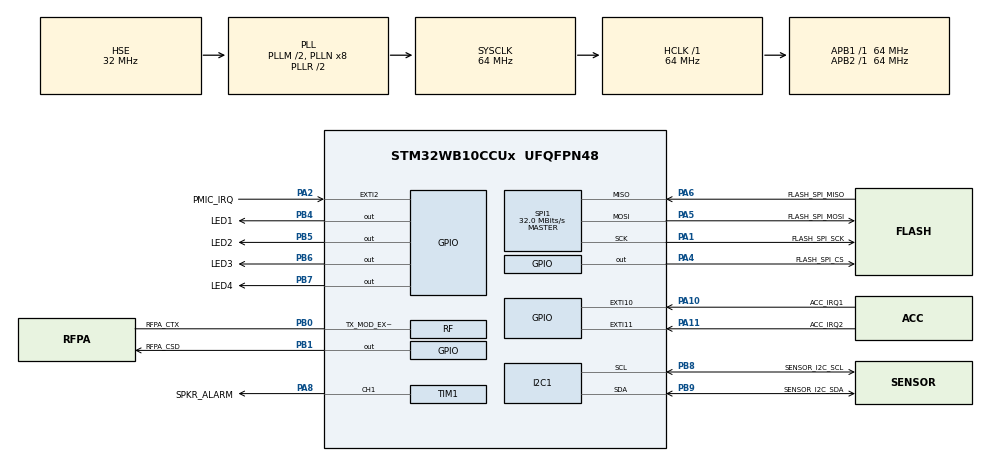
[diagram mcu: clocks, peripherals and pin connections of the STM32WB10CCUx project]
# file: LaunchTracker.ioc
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I2C1.Timing=0x10707DBC
Mcu.Family=STM32WB
Mcu.Name=STM32WB10CCUx
Mcu.Package=UFQFPN48
NVIC.EXTI15_10_IRQn=true\:0\:0\:false\:false\:true\:true\:true\:true
NVIC.HSEM_IRQn=true\:0\:0\:false\:false\:true\:false\:true\:true
NVIC.IPCC_C1_RX_IRQn=true\:0\:0\:false\:false\:true\:true\:true\:true
NVIC.IPCC_C1_TX_IRQn=true\:0\:0\:false\:false\:true\:true\:true\:true
NVIC.PriorityGroup=NVIC_PRIORITYGROUP_4
OSC_IN.Mode=HSE-External-Oscillator
OSC_IN.Signal=RCC_OSC_IN
OSC_OUT.Mode=HSE-External-Oscillator
OSC_OUT.Signal=RCC_OSC_OUT
PA1.GPIO_Label=FLASH_SPI_SCK
PA1.Mode=Full_Duplex_Master
PA1.Signal=SPI1_SCK
PA10.GPIO_Label=ACC_IRQ1
PA10.GPIO_ModeDefaultEXTI=GPIO_MODE_IT_FALLING
PA10.GPIO_PuPd=GPIO_PULLUP
PA10.Signal=GPXTI10
PA11.GPIO_Label=ACC_IRQ2
PA11.GPIO_ModeDefaultEXTI=GPIO_MODE_IT_FALLING
PA11.GPIO_PuPd=GPIO_PULLUP
PA11.Signal=GPXTI11
PA13.Mode=Trace_Asynchronous_SW
PA13.Signal=SYS_JTMS-SWDIO
PA14.Mode=Trace_Asynchronous_SW
PA14.Signal=SYS_JTCK-SWCLK
PA2.GPIO_Label=PMIC_IRQ
PA2.GPIO_ModeDefaultEXTI=GPIO_MODE_IT_FALLING
PA2.GPIO_PuPd=GPIO_PULLUP
PA2.Signal=GPXTI2
PA4.GPIO_Label=FLASH_SPI_CS
PA4.GPIO_ModeDefaultOutputPP=GPIO_MODE_OUTPUT_OD
PA4.GPIO_PuPd=GPIO_PULLUP
PA4.PinState=GPIO_PIN_SET
PA4.Signal=GPIO_Output
PA5.GPIO_Label=FLASH_SPI_MOSI
PA5.Mode=Full_Duplex_Master
PA5.Signal=SPI1_MOSI
PA6.GPIO_Label=FLASH_SPI_MISO
PA6.Mode=Full_Duplex_Master
PA6.Signal=SPI1_MISO
PA8.GPIO_Label=SPKR_ALARM
PA8.Signal=S_TIM1_CH1
PB0.GPIO_Label=RFPA_CTX
PB0.Mode=TX_MOD_EXT_PA
PB0.Signal=RF_TX_MOD_EXT_PA
PB1.GPIO_Label=RFPA_CSD
PB1.Signal=GPIO_Output
PB3.Mode=Trace_Asynchronous_SW
PB3.Signal=SYS_JTDO-SWO
PB4.GPIO_Label=LED1
PB4.Signal=GPIO_Output
PB5.GPIO_Label=LED2
PB5.Signal=GPIO_Output
PB6.GPIO_Label=LED3
PB6.Signal=GPIO_Output
PB7.GPIO_Label=LED4
PB7.Signal=GPIO_Output
PB8.GPIO_Label=SENSOR_I2C_SCL
PB8.Mode=I2C
PB8.Signal=I2C1_SCL
PB9.GPIO_Label=SENSOR_I2C_SDA
PB9.Mode=I2C
PB9.Signal=I2C1_SDA
PC14-OSC32_IN.Mode=LSE-External-Oscillator
PC14-OSC32_IN.Signal=RCC_OSC32_IN
PC15-OSC32_OUT.Mode=LSE-External-Oscillator
PC15-OSC32_OUT.Signal=RCC_OSC32_OUT
ProjectManager.HeapSize=0x200
ProjectManager.StackSize=0x400
ProjectManager.TargetToolchain=STM32CubeIDE
RCC.ADCFreq_Value=64000000
RCC.AHB2CLKDivider=RCC_SYSCLK_DIV2
RCC.AHBFreq_Value=64000000
RCC.APB1Freq_Value=64000000
RCC.APB1TimFreq_Value=64000000
RCC.APB2Freq_Value=64000000
RCC.APB2TimFreq_Value=64000000
RCC.APB3Freq_Value=16000000
RCC.CortexFreq_Value=64000000
RCC.HCLKFreq_Value=64000000
RCC.HSE_VALUE=32000000
RCC.HSI_VALUE=16000000
RCC.PLLM=RCC_PLLM_DIV2
RCC.PLLSourceVirtual=RCC_PLLSOURCE_HSE
RCC.RFWKPClockSelection=RCC_RFWKPCLKSOURCE_LSE
RCC.RTCClockSelection=RCC_RTCCLKSOURCE_LSE
RCC.SYSCLKFreq_VALUE=64000000
RCC.SYSCLKSource=RCC_SYSCLKSOURCE_PLLCLK
RCC.VCOOutputFreq_Value=128000000
RF1.Mode=RF1_Activate
RF1.Signal=RF_RF1
SH.S_TIM1_CH1.0=TIM1_CH1,PWM Generation1 CH1
SPI1.CalculateBaudRate=32.0 MBits/s
SPI1.Direction=SPI_DIRECTION_2LINES
SPI1.Mode=SPI_MODE_MASTER
SPI1.VirtualType=VM_MASTER
STM32_WPAN.CFG_LPM_SUPPORTED=1
STM32_WPAN.CFG_TX_POWER=(0x1D) /* 4dBm */
TIM1.Channel-PWM\ Generation1\ CH1=TIM_CHANNEL_1
VP_HSEM_VS_HSEM.Mode=HSEM_Activate
VP_IPCC_VS_IPCC.Mode=IPCC_Activate
VP_MEMORYMAP_VS_MEMORYMAP.Mode=CurAppReg
VP_RTC_VS_RTC_Activate.Mode=RTC_Enabled
VP_SEQUENCER_VS_SEQUENCER.Mode=SEQUENCER_Enabled
VP_STM32_WPAN_VS_BLE_HOST.Mode=STM32_WPAN_Enabled
VP_TINY_LPM_VS_TINY_LPM.Mode=TINY_LPM_Enabled
board=custom

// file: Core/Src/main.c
/* USER CODE BEGIN Header */
/**
  ******************************************************************************
  * @file           : main.c
  * @brief          : Main program body
  ******************************************************************************
  * @attention
  *
  * Copyright (c) 2024 STMicroelectronics.
  * All rights reserved.
  *
  * This software is licensed under terms that can be found in the LICENSE file
  * in the root directory of this software component.
  * If no LICENSE file comes with this software, it is provided AS-IS.
  *
  ******************************************************************************
  */
/* USER CODE END Header */
#include "main.h"

/* USER CODE BEGIN Includes */
#include "LT_App.h"
/* USER CODE END Includes */

I2C_HandleTypeDef hi2c1;

IPCC_HandleTypeDef hipcc;

RTC_HandleTypeDef hrtc;

SPI_HandleTypeDef hspi1;

TIM_HandleTypeDef htim1;

void SystemClock_Config(void);
void PeriphCommonClock_Config(void);
static void MX_GPIO_Init(void);
static void MX_I2C1_Init(void);
static void MX_IPCC_Init(void);
static void MX_RTC_Init(void);
static void MX_SPI1_Init(void);
static void MX_TIM1_Init(void);
static void MX_RF_Init(void);

int main(void)
{

  /* MCU Configuration--------------------------------------------------------*/

  /* Reset of all peripherals, Initializes the Flash interface and the Systick. */
  HAL_Init();
  /* Config code for STM32_WPAN (HSE Tuning must be done before system clock configuration) */
  MX_APPE_Config();

  /* Configure the system clock */
  SystemClock_Config();

/* Configure the peripherals common clocks */
  PeriphCommonClock_Config();

  /* IPCC initialisation */
  MX_IPCC_Init();

  /* Initialize all configured peripherals */
  MX_GPIO_Init();
  MX_I2C1_Init();
  MX_RTC_Init();
  MX_SPI1_Init();
  MX_TIM1_Init();
  MX_RF_Init();
  /* USER CODE BEGIN 2 */
//  ltHWInit();
  /* USER CODE END 2 */

  /* Init code for STM32_WPAN */
  MX_APPE_Init();

  /* Infinite loop */
  while (1)
  {
    MX_APPE_Process();

  }
}

void SystemClock_Config(void)
{
  RCC_OscInitTypeDef RCC_OscInitStruct = {0};
  RCC_ClkInitTypeDef RCC_ClkInitStruct = {0};

  /** Configure LSE Drive Capability
  */
  HAL_PWR_EnableBkUpAccess();
  __HAL_RCC_LSEDRIVE_CONFIG(RCC_LSEDRIVE_MEDIUMHIGH);

  /** Initializes the RCC Oscillators according to the specified parameters
  * in the RCC_OscInitTypeDef structure.
  */
  RCC_OscInitStruct.OscillatorType = RCC_OSCILLATORTYPE_HSI|RCC_OSCILLATORTYPE_HSE
                              |RCC_OSCILLATORTYPE_LSE;
  RCC_OscInitStruct.HSEState = RCC_HSE_ON;
  RCC_OscInitStruct.LSEState = RCC_LSE_ON;
  RCC_OscInitStruct.HSIState = RCC_HSI_ON;
  RCC_OscInitStruct.HSICalibrationValue = RCC_HSICALIBRATION_DEFAULT;
  RCC_OscInitStruct.PLL.PLLState = RCC_PLL_ON;
  RCC_OscInitStruct.PLL.PLLSource = RCC_PLLSOURCE_HSE;
  RCC_OscInitStruct.PLL.PLLM = RCC_PLLM_DIV2;
  RCC_OscInitStruct.PLL.PLLN = 8;
  RCC_OscInitStruct.PLL.PLLP = RCC_PLLP_DIV2;
  RCC_OscInitStruct.PLL.PLLR = RCC_PLLR_DIV2;
  RCC_OscInitStruct.PLL.PLLQ = RCC_PLLQ_DIV2;
  if (HAL_RCC_OscConfig(&RCC_OscInitStruct) != HAL_OK)
  {
    Error_Handler();
  }

  /** Configure the SYSCLKSource, HCLK, PCLK1 and PCLK2 clocks dividers
  */
  RCC_ClkInitStruct.ClockType = RCC_CLOCKTYPE_HCLK4|RCC_CLOCKTYPE_HCLK2
                              |RCC_CLOCKTYPE_HCLK|RCC_CLOCKTYPE_SYSCLK
                              |RCC_CLOCKTYPE_PCLK1|RCC_CLOCKTYPE_PCLK2;
  RCC_ClkInitStruct.SYSCLKSource = RCC_SYSCLKSOURCE_PLLCLK;
  RCC_ClkInitStruct.AHBCLKDivider = RCC_SYSCLK_DIV1;
  RCC_ClkInitStruct.APB1CLKDivider = RCC_HCLK_DIV1;
  RCC_ClkInitStruct.APB2CLKDivider = RCC_HCLK_DIV1;
  RCC_ClkInitStruct.AHBCLK2Divider = RCC_SYSCLK_DIV2;
  RCC_ClkInitStruct.AHBCLK4Divider = RCC_SYSCLK_DIV1;

  if (HAL_RCC_ClockConfig(&RCC_ClkInitStruct, FLASH_LATENCY_3) != HAL_OK)
  {
    Error_Handler();
  }
}

void PeriphCommonClock_Config(void)
{
  RCC_PeriphCLKInitTypeDef PeriphClkInitStruct = {0};

  /** Initializes the peripherals clock
  */
  PeriphClkInitStruct.PeriphClockSelection = RCC_PERIPHCLK_RFWAKEUP;
  PeriphClkInitStruct.RFWakeUpClockSelection = RCC_RFWKPCLKSOURCE_LSE;
  if (HAL_RCCEx_PeriphCLKConfig(&PeriphClkInitStruct) != HAL_OK)
  {
    Error_Handler();
  }
}

static void MX_I2C1_Init(void)
{

  hi2c1.Instance = I2C1;
  hi2c1.Init.Timing = 0x10707DBC;
  hi2c1.Init.OwnAddress1 = 0;
  hi2c1.Init.AddressingMode = I2C_ADDRESSINGMODE_7BIT;
  hi2c1.Init.DualAddressMode = I2C_DUALADDRESS_DISABLE;
  hi2c1.Init.OwnAddress2 = 0;
  hi2c1.Init.OwnAddress2Masks = I2C_OA2_NOMASK;
  hi2c1.Init.GeneralCallMode = I2C_GENERALCALL_DISABLE;
  hi2c1.Init.NoStretchMode = I2C_NOSTRETCH_DISABLE;
  if (HAL_I2C_Init(&hi2c1) != HAL_OK)
  {
    Error_Handler();
  }

  /** Configure Analogue filter
  */
  if (HAL_I2CEx_ConfigAnalogFilter(&hi2c1, I2C_ANALOGFILTER_ENABLE) != HAL_OK)
  {
    Error_Handler();
  }

  /** Configure Digital filter
  */
  if (HAL_I2CEx_ConfigDigitalFilter(&hi2c1, 0) != HAL_OK)
  {
    Error_Handler();
  }

}

static void MX_IPCC_Init(void)
{

  hipcc.Instance = IPCC;
  if (HAL_IPCC_Init(&hipcc) != HAL_OK)
  {
    Error_Handler();
  }

}

static void MX_RF_Init(void)
{

}

static void MX_RTC_Init(void)
{

  /** Initialize RTC Only
  */
  hrtc.Instance = RTC;
  hrtc.Init.HourFormat = RTC_HOURFORMAT_24;
  hrtc.Init.AsynchPrediv = CFG_RTC_ASYNCH_PRESCALER;
  hrtc.Init.SynchPrediv = CFG_RTC_SYNCH_PRESCALER;
  hrtc.Init.OutPut = RTC_OUTPUT_DISABLE;
  hrtc.Init.OutPutPolarity = RTC_OUTPUT_POLARITY_HIGH;
  hrtc.Init.OutPutRemap = RTC_OUTPUT_REMAP_NONE;
  if (HAL_RTC_Init(&hrtc) != HAL_OK)
  {
    Error_Handler();
  }

}

static void MX_SPI1_Init(void)
{

  /* SPI1 parameter configuration*/
  hspi1.Instance = SPI1;
  hspi1.Init.Mode = SPI_MODE_MASTER;
  hspi1.Init.Direction = SPI_DIRECTION_2LINES;
  hspi1.Init.DataSize = SPI_DATASIZE_8BIT;
  hspi1.Init.CLKPolarity = SPI_POLARITY_LOW;
  hspi1.Init.CLKPhase = SPI_PHASE_1EDGE;
  hspi1.Init.NSS = SPI_NSS_SOFT;
  hspi1.Init.BaudRatePrescaler = SPI_BAUDRATEPRESCALER_2;
  hspi1.Init.FirstBit = SPI_FIRSTBIT_MSB;
  hspi1.Init.TIMode = SPI_TIMODE_DISABLE;
  hspi1.Init.CRCCalculation = SPI_CRCCALCULATION_DISABLE;
  hspi1.Init.CRCPolynomial = 7;
  hspi1.Init.CRCLength = SPI_CRC_LENGTH_DATASIZE;
  hspi1.Init.NSSPMode = SPI_NSS_PULSE_ENABLE;
  if (HAL_SPI_Init(&hspi1) != HAL_OK)
  {
    Error_Handler();
  }

}

static void MX_TIM1_Init(void)
{

  TIM_MasterConfigTypeDef sMasterConfig = {0};
  TIM_OC_InitTypeDef sConfigOC = {0};
  TIM_BreakDeadTimeConfigTypeDef sBreakDeadTimeConfig = {0};

  htim1.Instance = TIM1;
  htim1.Init.Prescaler = 0;
  htim1.Init.CounterMode = TIM_COUNTERMODE_UP;
  htim1.Init.Period = 65535;
  htim1.Init.ClockDivision = TIM_CLOCKDIVISION_DIV1;
  htim1.Init.RepetitionCounter = 0;
  htim1.Init.AutoReloadPreload = TIM_AUTORELOAD_PRELOAD_DISABLE;
  if (HAL_TIM_PWM_Init(&htim1) != HAL_OK)
  {
    Error_Handler();
  }
  sMasterConfig.MasterOutputTrigger = TIM_TRGO_RESET;
  sMasterConfig.MasterOutputTrigger2 = TIM_TRGO2_RESET;
  sMasterConfig.MasterSlaveMode = TIM_MASTERSLAVEMODE_DISABLE;
  if (HAL_TIMEx_MasterConfigSynchronization(&htim1, &sMasterConfig) != HAL_OK)
  {
    Error_Handler();
  }
  sConfigOC.OCMode = TIM_OCMODE_PWM1;
  sConfigOC.Pulse = 0;
  sConfigOC.OCPolarity = TIM_OCPOLARITY_HIGH;
  sConfigOC.OCNPolarity = TIM_OCNPOLARITY_HIGH;
  sConfigOC.OCFastMode = TIM_OCFAST_DISABLE;
  sConfigOC.OCIdleState = TIM_OCIDLESTATE_RESET;
  sConfigOC.OCNIdleState = TIM_OCNIDLESTATE_RESET;
  if (HAL_TIM_PWM_ConfigChannel(&htim1, &sConfigOC, TIM_CHANNEL_1) != HAL_OK)
  {
    Error_Handler();
  }
  sBreakDeadTimeConfig.OffStateRunMode = TIM_OSSR_DISABLE;
  sBreakDeadTimeConfig.OffStateIDLEMode = TIM_OSSI_DISABLE;
  sBreakDeadTimeConfig.LockLevel = TIM_LOCKLEVEL_OFF;
  sBreakDeadTimeConfig.DeadTime = 0;
  sBreakDeadTimeConfig.BreakState = TIM_BREAK_DISABLE;
  sBreakDeadTimeConfig.BreakPolarity = TIM_BREAKPOLARITY_HIGH;
  sBreakDeadTimeConfig.BreakFilter = 0;
  sBreakDeadTimeConfig.BreakAFMode = TIM_BREAK_AFMODE_INPUT;
  sBreakDeadTimeConfig.Break2State = TIM_BREAK2_DISABLE;
  sBreakDeadTimeConfig.Break2Polarity = TIM_BREAK2POLARITY_HIGH;
  sBreakDeadTimeConfig.Break2Filter = 0;
  sBreakDeadTimeConfig.Break2AFMode = TIM_BREAK_AFMODE_INPUT;
  sBreakDeadTimeConfig.AutomaticOutput = TIM_AUTOMATICOUTPUT_DISABLE;
  if (HAL_TIMEx_ConfigBreakDeadTime(&htim1, &sBreakDeadTimeConfig) != HAL_OK)
  {
    Error_Handler();
  }
  HAL_TIM_MspPostInit(&htim1);

}

static void MX_GPIO_Init(void)
{
  GPIO_InitTypeDef GPIO_InitStruct = {0};

  /* GPIO Ports Clock Enable */
  __HAL_RCC_GPIOC_CLK_ENABLE();
  __HAL_RCC_GPIOB_CLK_ENABLE();
  __HAL_RCC_GPIOA_CLK_ENABLE();

  /*Configure GPIO pin Output Level */
  HAL_GPIO_WritePin(FLASH_SPI_CS_GPIO_Port, FLASH_SPI_CS_Pin, GPIO_PIN_SET);

  /*Configure GPIO pin Output Level */
  HAL_GPIO_WritePin(GPIOB, RFPA_CSD_Pin|LED1_Pin|LED2_Pin|LED3_Pin
                          |LED4_Pin, GPIO_PIN_RESET);

  /*Configure GPIO pins : PMIC_IRQ_Pin ACC_IRQ1_Pin ACC_IRQ2_Pin */
  GPIO_InitStruct.Pin = PMIC_IRQ_Pin|ACC_IRQ1_Pin|ACC_IRQ2_Pin;
  GPIO_InitStruct.Mode = GPIO_MODE_IT_FALLING;
  GPIO_InitStruct.Pull = GPIO_PULLUP;
  HAL_GPIO_Init(GPIOA, &GPIO_InitStruct);

  /*Configure GPIO pin : FLASH_SPI_CS_Pin */
  GPIO_InitStruct.Pin = FLASH_SPI_CS_Pin;
  GPIO_InitStruct.Mode = GPIO_MODE_OUTPUT_OD;
  GPIO_InitStruct.Pull = GPIO_PULLUP;
  GPIO_InitStruct.Speed = GPIO_SPEED_FREQ_LOW;
  HAL_GPIO_Init(FLASH_SPI_CS_GPIO_Port, &GPIO_InitStruct);

  /*Configure GPIO pins : RFPA_CSD_Pin LED1_Pin LED2_Pin LED3_Pin
                           LED4_Pin */
  GPIO_InitStruct.Pin = RFPA_CSD_Pin|LED1_Pin|LED2_Pin|LED3_Pin
                          |LED4_Pin;
  GPIO_InitStruct.Mode = GPIO_MODE_OUTPUT_PP;
  GPIO_InitStruct.Pull = GPIO_NOPULL;
  GPIO_InitStruct.Speed = GPIO_SPEED_FREQ_LOW;
  HAL_GPIO_Init(GPIOB, &GPIO_InitStruct);

  /* EXTI interrupt init*/
  HAL_NVIC_SetPriority(EXTI15_10_IRQn, 0, 0);
  HAL_NVIC_EnableIRQ(EXTI15_10_IRQn);

/* USER CODE BEGIN MX_GPIO_Init_2 */

  // Initialize PB0 as RF Power Amplifier CTX
  GPIO_InitStruct.Pin = RFPA_CTX_Pin;
  GPIO_InitStruct.Pull = GPIO_NOPULL;
  GPIO_InitStruct.Mode = GPIO_MODE_AF_PP;
  GPIO_InitStruct.Speed = GPIO_SPEED_FREQ_HIGH;
  GPIO_InitStruct.Alternate = GPIO_AF6_RF_DTB0;
  HAL_GPIO_Init(RFPA_CTX_GPIO_Port, &GPIO_InitStruct);

  // Initialize PB1 as RF Power Amplifier CSD
  GPIO_InitStruct.Pin = RFPA_CSD_Pin;
  GPIO_InitStruct.Pull = GPIO_NOPULL;
  GPIO_InitStruct.Mode = GPIO_MODE_OUTPUT_PP;
  GPIO_InitStruct.Speed = GPIO_SPEED_FREQ_HIGH;
  HAL_GPIO_Init(RFPA_CSD_GPIO_Port, &GPIO_InitStruct);

/* USER CODE END MX_GPIO_Init_2 */
}

void Error_Handler(void)
{
  /* USER CODE BEGIN Error_Handler_Debug */
  /* User can add his own implementation to report the HAL error return state */
  __disable_irq();

  HAL_GPIO_WritePin(GPIOB, LED4_Pin, 1);

  while (1)
  {
  }
  /* USER CODE END Error_Handler_Debug */
}
